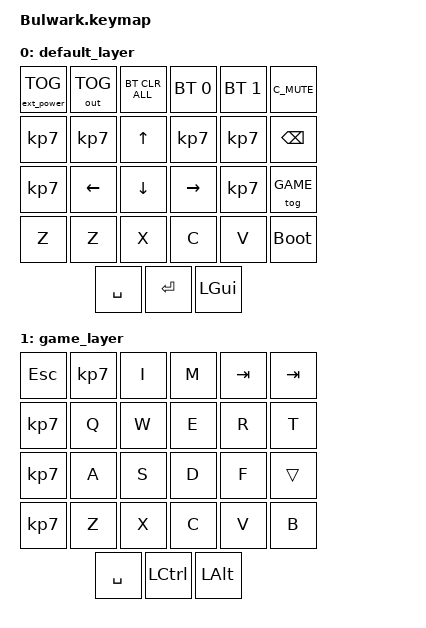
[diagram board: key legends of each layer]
/*
 * Copyright (c) 2020 The ZMK Contributors
 *
 * SPDX-License-Identifier: MIT
 */
 
#include <behaviors.dtsi>
#include <dt-bindings/zmk/keys.h>
#include <dt-bindings/zmk/bt.h>
#include <dt-bindings/zmk/ext_power.h>
#include <dt-bindings/zmk/outputs.h>

/ {

#define DEFAULT   0
#define GAME      1

//=====================================================================================================
//  behaviors {
/
//      };
//=====================================================================================================
//  combos {
//
//      };
//=====================================================================================================

    keymap {
        compatible = "zmk,keymap";

        default_layer {
    // ---------------------------------------------------------------------------------------------------
            bindings = <
//               _____________   _____________   _____________   _____________   _____________      ______
//              |     lock    | |  togBLE&USB | |    BTCLR    | |      BT1    | |     BT2     |    | EN_# |
               &ext_power EP_TOG  &out OUT_TOG   &bt BT_CLR_ALL   &bt BT_SEL 0    &bt BT_SEL 1      C_MUTE
//              |_____________| |_____________| |_____________| |_____________| |_____________|    |______|
//               _____________   _____________   _____________   _____________   _____________   _____________
//              |     ###     | |     ###     | |      UP     | |     ###     | |     ###     | |     BSPC    |
                    &kp KP_N7       &kp KP_N7        &kp UP       &kp KP_N7        &kp KP_N7        &kp BSPC
//              |_____________| |_____________| |_____________| |_____________| |_____________| |_____________|
//               _____________   _____________   _____________   _____________   _____________   _____________
//              |     ###     | |     LEFT    | |     DOWN    | |     RIGHT   | |     ###     | |    Layer2   |
                    &kp KP_N7       &kp LEFT        &kp DOWN        &kp RIGHT       &kp KP_N7      &tog GAME
//              |_____________| |_____________| |_____________| |_____________| |_____________| |_____________|
//               _____________   _____________   _____________   _____________   _____________   _____________
//              |     ###     | |      Z      | |      X      | |      C      | |      V      | |     BOOT    |
                    &kp Z           &kp Z            &kp X           &kp C           &kp V        &bootloader
//              |_____________| |_____________| |_____________| |_____________| |_____________| |_____________|
//       _____________   _____________   _____________
//      |     SPACE   | |    ENTER    | |   COMMAND   |
            &kp SPACE       &kp RET        &kp LGUI
//      |_____________| |_____________| |_____________|
            >;
            
            sensor-bindings =
                <&inc_dec_kp C_VOL_UP C_VOL_DN>;
        };
    // ---------------------------------------------------------------------------------------------------
        
        game_layer {
    // ---------------------------------------------------------------------------------------------------
            bindings = <
//               _____________   _____________   _____________   _____________   _____________      ______
//              |     ESC     | |     PWR     | |      I      | |      M      | |     TAB     |    | EN_# |
                    &kp ESC        &kp KP_N7         &kp I           &kp M          &kp TAB        &kp TAB
//              |_____________| |_____________| |_____________| |_____________| |_____________|    |______|
//               _____________   _____________   _____________   _____________   _____________   _____________
//              |     ###     | |      Q      | |      W      | |      E      | |      R      | |      T      |
                    &kp KP_N7        &kp Q          &kp W           &kp E            &kp R           &kp T
//              |_____________| |_____________| |_____________| |_____________| |_____________| |_____________|
//               _____________   _____________   _____________   _____________   _____________   _____________
//              |     ###     | |      A      | |      S      | |      D      | |      F      | |    trans    |
                    &kp KP_N7        &kp A           &kp S           &kp D           &kp F           &trans
//              |_____________| |_____________| |_____________| |_____________| |_____________| |_____________|
//               _____________   _____________   _____________   _____________   _____________   _____________
//              |     ###     | |      Z      | |      X      | |      C      | |      V      | |      B      |
                    &kp KP_N7       &kp Z            &kp X           &kp C           &kp V           &kp B
//              |_____________| |_____________| |_____________| |_____________| |_____________| |_____________|
//       _____________   _____________   _____________
//      |    SPACE    | |     CRTL    | |     ALT     |
            &kp SPACE      &kp LCTRL        &kp LALT
//      |_____________| |_____________| |_____________|
            >;
            
            sensor-bindings =
                <&inc_dec_kp C_VOL_UP C_VOL_DN>;
        };
    };
 //=====================================================================================================
};
